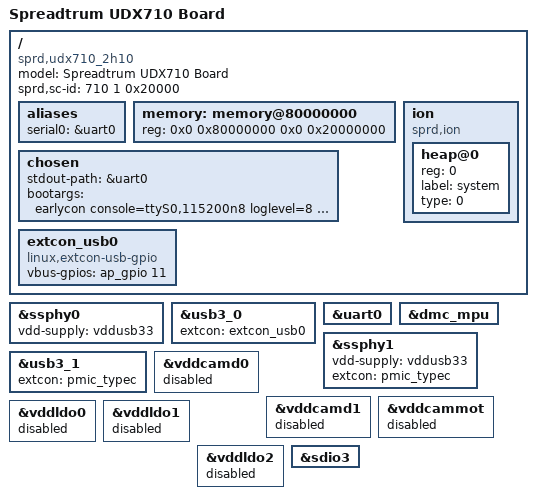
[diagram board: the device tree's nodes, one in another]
/*
 * Spreadtrum orca udx710 board DTS file
 *
 * Copyright (C) 2017,2018 Spreadtrum Communications Inc.
 *
 * This file is licensed under a dual GPLv2 or X11 license.
 */
/dts-v1/;

#include <dt-bindings/gpio/gpio.h>

#include "udx710.dtsi"
#include "sc2730.dtsi"
#include "udx710-mach.dtsi"

/ {
	model = "Spreadtrum UDX710 Board";

	compatible = "sprd,udx710_2h10", "sprd,udx710";

	sprd,sc-id = <710 1 0x20000>;

	aliases {
		serial0 = &uart0;
	};

	memory: memory@80000000 {
		device_type = "memory";
		reg = <0x0 0x80000000 0x0 0x20000000>;
	};

	chosen {
		stdout-path = &uart0;
		bootargs = "earlycon console=ttyS0,115200n8 loglevel=8 init=/init root=/dev/ram0 ro androidboot.hardware=udx710_2h10 androidboot.selinux=permissive swiotlb=64k androidboot.dtbo_idx=0 printk.devkmsg=on";
	};

	ion {
		compatible = "sprd,ion";
		#address-cells = <1>;
		#size-cells = <0>;

		heap@0 {
			reg = <0>;
			label = "system";
			type = <0>;
		};
	};

	extcon_usb0: extcon_usb0 {
		compatible = "linux,extcon-usb-gpio";

		vbus-gpios = <&ap_gpio 11 GPIO_ACTIVE_HIGH>;
	};
};

&ssphy0 {
	vdd-supply = <&vddusb33>;
	status = "okay";
};

&usb3_0 {
	extcon = <&extcon_usb0>;
	status = "okay";
};

&uart0 {
	status = "ok";
};

&dmc_mpu {
	status = "okay";
};

&ssphy1 {
	vdd-supply = <&vddusb33>;
	extcon = <&pmic_typec>;
	status = "okay";
};

&usb3_1 {
	extcon = <&pmic_typec>;
	status = "okay";
};

&vddcamd0 {
	status = "disabled";
};

&vddcamd1 {
	status = "disabled";
};

&vddcammot {
	status = "disabled";
};

&vddldo0 {
	status = "disabled";
};

&vddldo1 {
	status = "disabled";
};

&vddldo2 {
	status = "disabled";
};

&sdio3 {
	status = "okay";
};
